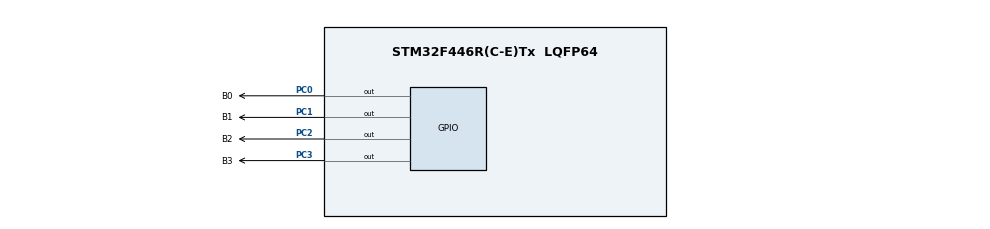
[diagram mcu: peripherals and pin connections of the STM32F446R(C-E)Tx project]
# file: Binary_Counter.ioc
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Mcu.Family=STM32F4
Mcu.Name=STM32F446R(C-E)Tx
Mcu.Package=LQFP64
NVIC.PriorityGroup=NVIC_PRIORITYGROUP_4
PC0.GPIO_Label=B0
PC0.Signal=GPIO_Output
PC1.GPIO_Label=B1
PC1.Signal=GPIO_Output
PC2.GPIO_Label=B2
PC2.Signal=GPIO_Output
PC3.GPIO_Label=B3
PC3.Signal=GPIO_Output
ProjectManager.HeapSize=0x200
ProjectManager.StackSize=0x400
ProjectManager.TargetToolchain=STM32CubeIDE
RCC.CortexFreq_Value=16000000
RCC.USBFreq_Value=96000000
RCC.VCOOutputFreq_Value=192000000
board=custom

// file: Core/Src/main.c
/* USER CODE BEGIN Header */
/**
 ******************************************************************************
 * @file           : main.c
 * @brief          : Main program body
 ******************************************************************************
 * @attention
 *
 * Copyright (c) 2024 STMicroelectronics.
 * All rights reserved.
 *
 * This software is licensed under terms that can be found in the LICENSE file
 * in the root directory of this software component.
 * If no LICENSE file comes with this software, it is provided AS-IS.
 *
 ******************************************************************************
 */
/* USER CODE END Header */
#include "main.h"

void SystemClock_Config(void);
static void MX_GPIO_Init(void);

int main(void)
{

  /* MCU Configuration--------------------------------------------------------*/

  /* Reset of all peripherals, Initializes the Flash interface and the Systick. */
  HAL_Init();

  /* Configure the system clock */
  SystemClock_Config();

  /* Initialize all configured peripherals */
  MX_GPIO_Init();
  /* USER CODE BEGIN 2 */
	uint8_t counter = 0;

  /* USER CODE END 2 */

  /* Infinite loop */
	while (1)
	{

    /* USER CODE BEGIN 3 */
		// Set PC0 to PC3 to binary counter value
		HAL_GPIO_WritePin(B0_GPIO_Port, B0_Pin, (counter & 0x01) ? GPIO_PIN_SET : GPIO_PIN_RESET);
		HAL_GPIO_WritePin(B1_GPIO_Port, B1_Pin, (counter & 0x02) ? GPIO_PIN_SET : GPIO_PIN_RESET);
		HAL_GPIO_WritePin(B2_GPIO_Port, B2_Pin, (counter & 0x04) ? GPIO_PIN_SET : GPIO_PIN_RESET);
		HAL_GPIO_WritePin(B3_GPIO_Port, B3_Pin, (counter & 0x08) ? GPIO_PIN_SET : GPIO_PIN_RESET);

		// Increment the counter
		counter = (counter + 1) & 0x0F;

		// Delay to simulate the timing
		HAL_Delay(500); // 500 ms delay, adjust as needed
	}
  /* USER CODE END 3 */
}

void SystemClock_Config(void)
{
  RCC_OscInitTypeDef RCC_OscInitStruct = {0};
  RCC_ClkInitTypeDef RCC_ClkInitStruct = {0};

  /** Configure the main internal regulator output voltage
  */
  __HAL_RCC_PWR_CLK_ENABLE();
  __HAL_PWR_VOLTAGESCALING_CONFIG(PWR_REGULATOR_VOLTAGE_SCALE3);

  /** Initializes the RCC Oscillators according to the specified parameters
  * in the RCC_OscInitTypeDef structure.
  */
  RCC_OscInitStruct.OscillatorType = RCC_OSCILLATORTYPE_HSI;
  RCC_OscInitStruct.HSIState = RCC_HSI_ON;
  RCC_OscInitStruct.HSICalibrationValue = RCC_HSICALIBRATION_DEFAULT;
  RCC_OscInitStruct.PLL.PLLState = RCC_PLL_NONE;
  if (HAL_RCC_OscConfig(&RCC_OscInitStruct) != HAL_OK)
  {
    Error_Handler();
  }

  /** Initializes the CPU, AHB and APB buses clocks
  */
  RCC_ClkInitStruct.ClockType = RCC_CLOCKTYPE_HCLK|RCC_CLOCKTYPE_SYSCLK
                              |RCC_CLOCKTYPE_PCLK1|RCC_CLOCKTYPE_PCLK2;
  RCC_ClkInitStruct.SYSCLKSource = RCC_SYSCLKSOURCE_HSI;
  RCC_ClkInitStruct.AHBCLKDivider = RCC_SYSCLK_DIV1;
  RCC_ClkInitStruct.APB1CLKDivider = RCC_HCLK_DIV1;
  RCC_ClkInitStruct.APB2CLKDivider = RCC_HCLK_DIV1;

  if (HAL_RCC_ClockConfig(&RCC_ClkInitStruct, FLASH_LATENCY_0) != HAL_OK)
  {
    Error_Handler();
  }
}

static void MX_GPIO_Init(void)
{
  GPIO_InitTypeDef GPIO_InitStruct = {0};

  /* GPIO Ports Clock Enable */
  __HAL_RCC_GPIOC_CLK_ENABLE();

  /*Configure GPIO pin Output Level */
  HAL_GPIO_WritePin(GPIOC, B0_Pin|B1_Pin|B2_Pin|B3_Pin, GPIO_PIN_RESET);

  /*Configure GPIO pins : B0_Pin B1_Pin B2_Pin B3_Pin */
  GPIO_InitStruct.Pin = B0_Pin|B1_Pin|B2_Pin|B3_Pin;
  GPIO_InitStruct.Mode = GPIO_MODE_OUTPUT_PP;
  GPIO_InitStruct.Pull = GPIO_NOPULL;
  GPIO_InitStruct.Speed = GPIO_SPEED_FREQ_LOW;
  HAL_GPIO_Init(GPIOC, &GPIO_InitStruct);

}

void Error_Handler(void)
{
	__disable_irq();
	while (1)
	{
	}
}
